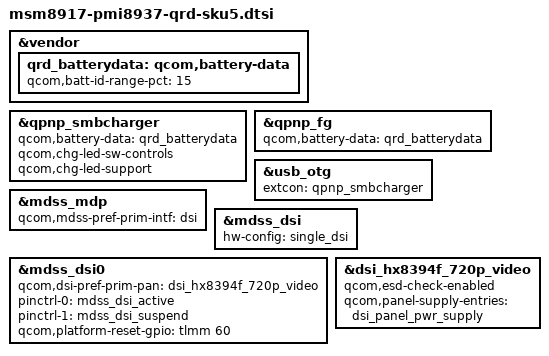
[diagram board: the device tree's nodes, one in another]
/*
 * Copyright (c) 2016, 2018, The Linux Foundation. All rights reserved.
 *
 * This program is free software; you can redistribute it and/or modify
 * it under the terms of the GNU General Public License version 2 and
 * only version 2 as published by the Free Software Foundation.
 *
 * This program is distributed in the hope that it will be useful,
 * but WITHOUT ANY WARRANTY; without even the implied warranty of
 * MERCHANTABILITY or FITNESS FOR A PARTICULAR PURPOSE.  See the
 * GNU General Public License for more details.
 */

#include "pmi8937.dtsi"
#include "msm8917-qrd.dtsi"
#include "msm8937-mdss-panels.dtsi"

&vendor{
	qrd_batterydata: qcom,battery-data {
		qcom,batt-id-range-pct = <15>;
		#include "batterydata-qrd-sku2-4v35-2590mah.dtsi"
	};
};

&qpnp_smbcharger {
	qcom,battery-data = <&qrd_batterydata>;
	qcom,chg-led-sw-controls;
	qcom,chg-led-support;
	/delete-property/ dpdm-supply;
};

&qpnp_fg {
	qcom,battery-data = <&qrd_batterydata>;
};

&usb_otg {
	extcon = <&qpnp_smbcharger>;
};

&mdss_mdp {
	qcom,mdss-pref-prim-intf = "dsi";
};

&mdss_dsi {
	hw-config = "single_dsi";
};

&mdss_dsi0 {
	qcom,dsi-pref-prim-pan = <&dsi_hx8394f_720p_video>;
	pinctrl-names = "mdss_default", "mdss_sleep";
	pinctrl-0 = <&mdss_dsi_active>;
	pinctrl-1 = <&mdss_dsi_suspend>;

	qcom,platform-reset-gpio = <&tlmm 60 0>;
};

&dsi_hx8394f_720p_video {
	qcom,esd-check-enabled;
	qcom,panel-supply-entries = <&dsi_panel_pwr_supply>;
};
